VERSION ""

NS_ :

BS_:

BU_: Device Host

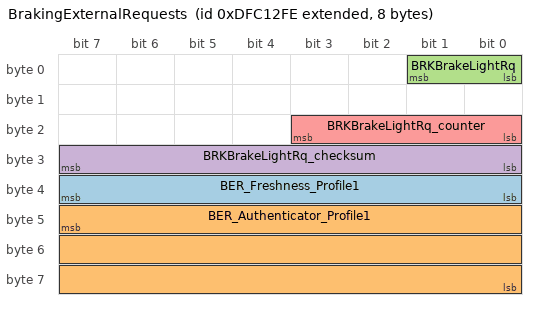
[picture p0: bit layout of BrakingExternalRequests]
BO_ 2382107390 BrakingExternalRequests: 8 Vector__XXX
 SG_ BER_Freshness_Profile1 : 39|8@0+ (1,0) [0|255] "" Vector__XXX
 SG_ BER_Authenticator_Profile1 : 47|24@0+ (1,0) [0|16777215] "" Vector__XXX
 SG_ BRKBrakeLightRq : 0|2@1+ (1,0) [0|3] "" Vector__XXX
 SG_ BRKBrakeLightRq_checksum : 24|8@1+ (1,0) [0|255] "" Vector__XXX
 SG_ BRKBrakeLightRq_counter : 16|4@1+ (1,0) [0|15] "" Vector__XXX

CM_ "
$DBC storage: //depot/auto/dbc/Software_Modules/Braking_System/BRK_ext/ $

";
CM_ BO_ 2382107390 "Message with general information about current Drivetrain System state";
BA_DEF_  "BusType" STRING ;
BA_DEF_  "DBName" STRING ;
BA_DEF_  "DatabaseVersion" STRING ;
BA_DEF_ BO_  "GenMsgCycleTime" INT 0 3600000;
BA_DEF_ BO_  "GenMsgILSupport" ENUM  "No","Yes";
BA_DEF_ BO_  "GenMsgRequestable" INT 0 1;
BA_DEF_ BO_  "GenMsgSendType" ENUM  "cyclic","NotUsed","NotUsed","NotUsed","NotUsed","NotUsed","NotUsed","IfActive","noMsgSendType";
BA_DEF_ SG_  "GenSigEVName" STRING ;
BA_DEF_ SG_  "GenSigILSupport" ENUM  "No","Yes";
BA_DEF_ SG_  "GenSigSendType" ENUM  "Cyclic","OnWrite","OnWriteWithRepetition","OnChange","OnChangeWithRepetition","IfActive","IfActiveWithRepetition","NoSigSendType";
BA_DEF_ SG_  "GenSigStartValue" INT 0 2147483647;
BA_DEF_ BU_  "NmStationAddress" INT 0 255;
BA_DEF_  "ProtocolType" STRING ;
BA_DEF_  "SAE_J1939_21_SpecVersion" STRING ;
BA_DEF_  "SAE_J1939_71_SpecVersion" STRING ;
BA_DEF_  "SAE_J1939_73_SpecVersion" STRING ;
BA_DEF_  "SAE_J1939_75_SpecVersion" STRING ;
BA_DEF_  "SAE_J1939_81_SpecVersion" STRING ;
BA_DEF_  "SAE_J1939_DA_SpecVersion" STRING ;
BA_DEF_ BO_  "Producer" STRING ;
BA_DEF_ SG_  "SigType" ENUM  "Default","Range","RangeSigned","ASCII","Discrete","Control","ReferencePGN","DTC","StringDelimiter","StringLength","StringLengthControl","MessageCounter","MessageChecksum";
BA_DEF_ BO_  "VFrameFormat" ENUM  "StandardCAN","ExtendedCAN","reserved","J1939PG","reserved","reserved","reserved","reserved","reserved","reserved","reserved","reserved","reserved","reserved","StandardCAN_FD","ExtendedCAN_FD";
BA_DEF_DEF_  "BusType" "";
BA_DEF_DEF_ "Producer" "BRK" ;
BA_DEF_DEF_  "DBName" "";
BA_DEF_DEF_  "DatabaseVersion" "";
BA_DEF_DEF_  "GenMsgCycleTime" 0;
BA_DEF_DEF_  "GenMsgILSupport" "Yes";
BA_DEF_DEF_  "GenMsgRequestable" 1;
BA_DEF_DEF_  "GenMsgSendType" "noMsgSendType";
BA_DEF_DEF_  "GenSigEVName" "Env@Nodename_@Signame";
BA_DEF_DEF_  "GenSigILSupport" "Yes";
BA_DEF_DEF_  "GenSigSendType" "NoSigSendType";
BA_DEF_DEF_  "GenSigStartValue" 0;
BA_DEF_DEF_  "NmStationAddress" 254;
BA_DEF_DEF_  "ProtocolType" "";
BA_DEF_DEF_  "SAE_J1939_21_SpecVersion" "";
BA_DEF_DEF_  "SAE_J1939_71_SpecVersion" "";
BA_DEF_DEF_  "SAE_J1939_73_SpecVersion" "";
BA_DEF_DEF_  "SAE_J1939_75_SpecVersion" "";
BA_DEF_DEF_  "SAE_J1939_81_SpecVersion" "";
BA_DEF_DEF_  "SAE_J1939_DA_SpecVersion" "";
BA_DEF_DEF_  "SigType" "Default";
BA_DEF_DEF_  "VFrameFormat" "J1939PG";
BA_ "BusType" "CAN";
BA_ "DatabaseVersion" "1.0";
BA_ "ProtocolType" "J1939";
BA_ "SAE_J1939_21_SpecVersion" "2006-10";
BA_ "SAE_J1939_71_SpecVersion" "2012-10";
BA_ "SAE_J1939_73_SpecVersion" "2012-10";
BA_ "SAE_J1939_75_SpecVersion" "2012-05";
BA_ "SAE_J1939_81_SpecVersion" "2012-05";
BA_ "SAE_J1939_DA_SpecVersion" "2015-01";
BA_ "DBName" "BRKBrakeLightRq";
BA_ "GenMsgSendType" BO_ 2382107390 0;
BA_ "GenMsgCycleTime" BO_ 2382107390 100;
BA_ "GenSigSendType" SG_ 2382107390 BRKBrakeLightRq_checksum 0;
BA_ "SigType" SG_ 2382107390 BRKBrakeLightRq_checksum 12;
BA_ "SigType" SG_ 2382107390 BRKBrakeLightRq_counter 11;
BA_ "GenSigSendType" SG_ 2382107390 BRKBrakeLightRq_counter 0;
VAL_ 2382107390 BRKBrakeLightRq 3 "Don't care/Take no action" 2 "Reserved" 1 "Turn brake light on" 0 "Turn brake light off" ;
